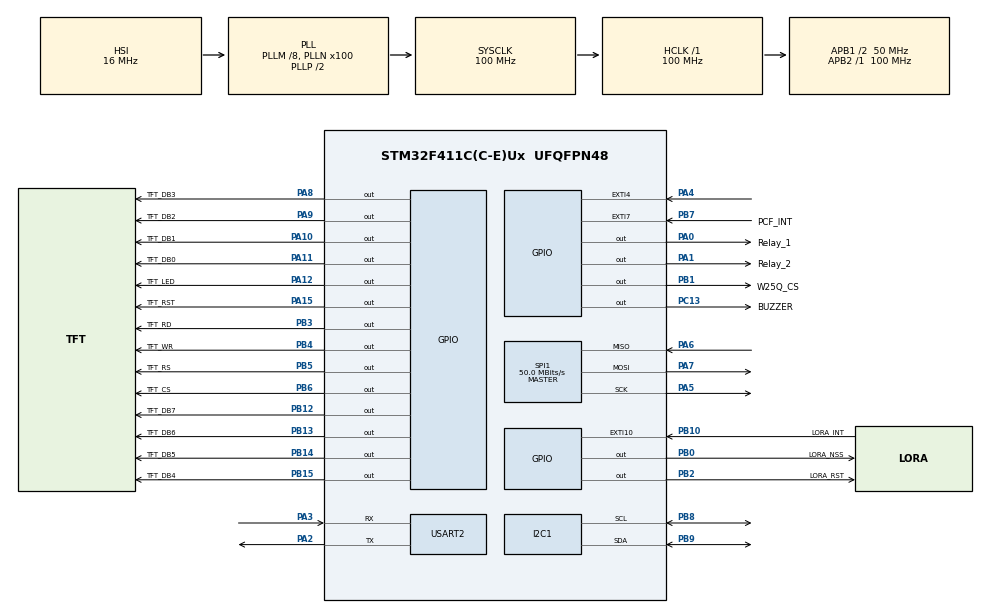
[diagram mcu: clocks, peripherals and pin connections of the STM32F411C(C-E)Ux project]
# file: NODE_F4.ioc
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FREERTOS.Tasks01=KeyMatrix_Task,0,128,StartKeyMatrix_Task,Default,NULL,Dynamic,NULL,NULL;TFT_Task,1,128,StartTFT_Task,Default,NULL,Dynamic,NULL,NULL
FREERTOS.configUSE_NEWLIB_REENTRANT=1
I2C1.DualAddressMode=I2C_DUALADDRESS_DISABLE
I2C1.GeneralCallMode=I2C_GENERALCALL_DISABLE
Mcu.Family=STM32F4
Mcu.Name=STM32F411C(C-E)Ux
Mcu.Package=UFQFPN48
NVIC.EXTI15_10_IRQn=true\:5\:0\:false\:false\:true\:true\:true\:true\:true
NVIC.EXTI9_5_IRQn=true\:5\:0\:false\:false\:true\:true\:true\:true\:true
NVIC.PriorityGroup=NVIC_PRIORITYGROUP_4
NVIC.TIM2_IRQn=true\:15\:0\:false\:false\:true\:false\:false\:true\:true
NVIC.TimeBase=TIM2_IRQn
NVIC.TimeBaseIP=TIM2
PA0-WKUP.GPIO_Label=Relay_1
PA0-WKUP.Signal=GPIO_Output
PA1.GPIO_Label=Relay_2
PA1.Signal=GPIO_Output
PA10.GPIO_Label=TFT_DB1
PA10.Signal=GPIO_Output
PA11.GPIO_Label=TFT_DB0
PA11.Signal=GPIO_Output
PA12.GPIO_Label=TFT_LED
PA12.Signal=GPIO_Output
PA13.Mode=Serial_Wire
PA13.Signal=SYS_JTMS-SWDIO
PA14.Mode=Serial_Wire
PA14.Signal=SYS_JTCK-SWCLK
PA15.GPIO_Label=TFT_RST
PA15.Signal=GPIO_Output
PA2.Mode=Asynchronous
PA2.Signal=USART2_TX
PA3.Mode=Asynchronous
PA3.Signal=USART2_RX
PA4.Signal=GPXTI4
PA5.Mode=Full_Duplex_Master
PA5.Signal=SPI1_SCK
PA6.Mode=Full_Duplex_Master
PA6.Signal=SPI1_MISO
PA7.Mode=Full_Duplex_Master
PA7.Signal=SPI1_MOSI
PA8.GPIO_Label=TFT_DB3
PA8.Signal=GPIO_Output
PA9.GPIO_Label=TFT_DB2
PA9.Signal=GPIO_Output
PB0.GPIO_Label=LORA_NSS
PB0.Signal=GPIO_Output
PB1.GPIO_Label=W25Q_CS
PB1.Signal=GPIO_Output
PB10.GPIO_Label=LORA_INT
PB10.Signal=GPXTI10
PB12.GPIO_Label=TFT_DB7
PB12.Signal=GPIO_Output
PB13.GPIO_Label=TFT_DB6
PB13.Signal=GPIO_Output
PB14.GPIO_Label=TFT_DB5
PB14.Signal=GPIO_Output
PB15.GPIO_Label=TFT_DB4
PB15.Signal=GPIO_Output
PB2.GPIO_Label=LORA_RST
PB2.Signal=GPIO_Output
PB3.GPIO_Label=TFT_RD
PB3.Signal=GPIO_Output
PB4.GPIO_Label=TFT_WR
PB4.Signal=GPIO_Output
PB5.GPIO_Label=TFT_RS
PB5.Signal=GPIO_Output
PB6.GPIO_Label=TFT_CS
PB6.Signal=GPIO_Output
PB7.GPIO_Label=PCF_INT
PB7.GPIO_ModeDefaultEXTI=GPIO_MODE_IT_FALLING
PB7.GPIO_PuPd=GPIO_PULLUP
PB7.Signal=GPXTI7
PB8.Mode=I2C
PB8.Signal=I2C1_SCL
PB9.Mode=I2C
PB9.Signal=I2C1_SDA
PC13-ANTI_TAMP.GPIO_Label=BUZZER
PC13-ANTI_TAMP.PinState=GPIO_PIN_RESET
PC13-ANTI_TAMP.Signal=GPIO_Output
PH0\ -\ OSC_IN.Mode=HSE-External-Oscillator
PH0\ -\ OSC_IN.Signal=RCC_OSC_IN
PH1\ -\ OSC_OUT.Mode=HSE-External-Oscillator
PH1\ -\ OSC_OUT.Signal=RCC_OSC_OUT
ProjectManager.HeapSize=0x200
ProjectManager.StackSize=0x400
ProjectManager.TargetToolchain=STM32CubeIDE
RCC.48MHZClocksFreq_Value=40000000
RCC.AHBFreq_Value=100000000
RCC.APB1CLKDivider=RCC_HCLK_DIV2
RCC.APB1Freq_Value=50000000
RCC.APB1TimFreq_Value=100000000
RCC.APB2Freq_Value=100000000
RCC.APB2TimFreq_Value=100000000
RCC.CortexFreq_Value=100000000
RCC.HCLKFreq_Value=100000000
RCC.HSE_VALUE=25000000
RCC.HSI_VALUE=16000000
RCC.LSE_VALUE=32768
RCC.PLLM=8
RCC.PLLN=100
RCC.PLLQ=5
RCC.SYSCLKFreq_VALUE=100000000
RCC.SYSCLKSource=RCC_SYSCLKSOURCE_PLLCLK
RCC.VCOOutputFreq_Value=200000000
SPI1.CalculateBaudRate=50.0 MBits/s
SPI1.Direction=SPI_DIRECTION_2LINES
SPI1.Mode=SPI_MODE_MASTER
SPI1.VirtualType=VM_MASTER
TIM3.Prescaler=71
USART2.VirtualMode=VM_ASYNC
VP_FREERTOS_VS_CMSIS_V1.Mode=CMSIS_V1
VP_SYS_VS_tim2.Mode=TIM2
VP_TIM3_VS_ClockSourceINT.Mode=Internal
board=custom

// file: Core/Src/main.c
/* USER CODE BEGIN Header */
/**
  ******************************************************************************
  * @file           : main.c
  * @brief          : Main program body
  ******************************************************************************
  * @attention
  *
  * Copyright (c) 2023 STMicroelectronics.
  * All rights reserved.
  *
  * This software is licensed under terms that can be found in the LICENSE file
  * in the root directory of this software component.
  * If no LICENSE file comes with this software, it is provided AS-IS.
  *
  ******************************************************************************
  */
/* USER CODE END Header */
#include "main.h"
#include "cmsis_os.h"

/* USER CODE BEGIN Includes */
#include "TFT.h"
/* USER CODE END Includes */

I2C_HandleTypeDef hi2c1;

SPI_HandleTypeDef hspi1;

TIM_HandleTypeDef htim3;

UART_HandleTypeDef huart2;

osThreadId KeyMatrix_TaskHandle;
osThreadId TFT_TaskHandle;

void SystemClock_Config(void);
static void MX_GPIO_Init(void);
static void MX_I2C1_Init(void);
static void MX_SPI1_Init(void);
static void MX_USART2_UART_Init(void);
static void MX_TIM3_Init(void);
void StartKeyMatrix_Task(void const * argument);
void StartTFT_Task(void const * argument);

int main(void)
{

  /* MCU Configuration--------------------------------------------------------*/

  /* Reset of all peripherals, Initializes the Flash interface and the Systick. */
  HAL_Init();

  /* Configure the system clock */
  SystemClock_Config();

  /* Initialize all configured peripherals */
  MX_GPIO_Init();
  MX_I2C1_Init();
  MX_SPI1_Init();
  MX_USART2_UART_Init();
  MX_TIM3_Init();
  /* USER CODE BEGIN 2 */
  TFT_init();
  /* USER CODE END 2 */

  /* Create the thread(s) */
  /* definition and creation of KeyMatrix_Task */
  osThreadDef(KeyMatrix_Task, StartKeyMatrix_Task, osPriorityNormal, 0, 128);
  KeyMatrix_TaskHandle = osThreadCreate(osThread(KeyMatrix_Task), NULL);

  /* definition and creation of TFT_Task */
  osThreadDef(TFT_Task, StartTFT_Task, osPriorityAboveNormal, 0, 128);
  TFT_TaskHandle = osThreadCreate(osThread(TFT_Task), NULL);

  /* Start scheduler */
  osKernelStart();

  /* We should never get here as control is now taken by the scheduler */
  /* Infinite loop */
  while (1)
  {

  }
}

void SystemClock_Config(void)
{
  RCC_OscInitTypeDef RCC_OscInitStruct = {0};
  RCC_ClkInitTypeDef RCC_ClkInitStruct = {0};

  /** Configure the main internal regulator output voltage
  */
  __HAL_RCC_PWR_CLK_ENABLE();
  __HAL_PWR_VOLTAGESCALING_CONFIG(PWR_REGULATOR_VOLTAGE_SCALE1);

  /** Initializes the RCC Oscillators according to the specified parameters
  * in the RCC_OscInitTypeDef structure.
  */
  RCC_OscInitStruct.OscillatorType = RCC_OSCILLATORTYPE_HSI;
  RCC_OscInitStruct.HSIState = RCC_HSI_ON;
  RCC_OscInitStruct.HSICalibrationValue = RCC_HSICALIBRATION_DEFAULT;
  RCC_OscInitStruct.PLL.PLLState = RCC_PLL_ON;
  RCC_OscInitStruct.PLL.PLLSource = RCC_PLLSOURCE_HSI;
  RCC_OscInitStruct.PLL.PLLM = 8;
  RCC_OscInitStruct.PLL.PLLN = 100;
  RCC_OscInitStruct.PLL.PLLP = RCC_PLLP_DIV2;
  RCC_OscInitStruct.PLL.PLLQ = 5;
  if (HAL_RCC_OscConfig(&RCC_OscInitStruct) != HAL_OK)
  {
    Error_Handler();
  }

  /** Initializes the CPU, AHB and APB buses clocks
  */
  RCC_ClkInitStruct.ClockType = RCC_CLOCKTYPE_HCLK|RCC_CLOCKTYPE_SYSCLK
                              |RCC_CLOCKTYPE_PCLK1|RCC_CLOCKTYPE_PCLK2;
  RCC_ClkInitStruct.SYSCLKSource = RCC_SYSCLKSOURCE_PLLCLK;
  RCC_ClkInitStruct.AHBCLKDivider = RCC_SYSCLK_DIV1;
  RCC_ClkInitStruct.APB1CLKDivider = RCC_HCLK_DIV2;
  RCC_ClkInitStruct.APB2CLKDivider = RCC_HCLK_DIV1;

  if (HAL_RCC_ClockConfig(&RCC_ClkInitStruct, FLASH_LATENCY_3) != HAL_OK)
  {
    Error_Handler();
  }
}

static void MX_I2C1_Init(void)
{

  hi2c1.Instance = I2C1;
  hi2c1.Init.ClockSpeed = 100000;
  hi2c1.Init.DutyCycle = I2C_DUTYCYCLE_2;
  hi2c1.Init.OwnAddress1 = 0;
  hi2c1.Init.AddressingMode = I2C_ADDRESSINGMODE_7BIT;
  hi2c1.Init.DualAddressMode = I2C_DUALADDRESS_DISABLE;
  hi2c1.Init.OwnAddress2 = 0;
  hi2c1.Init.GeneralCallMode = I2C_GENERALCALL_DISABLE;
  hi2c1.Init.NoStretchMode = I2C_NOSTRETCH_DISABLE;
  if (HAL_I2C_Init(&hi2c1) != HAL_OK)
  {
    Error_Handler();
  }

}

static void MX_SPI1_Init(void)
{

  /* SPI1 parameter configuration*/
  hspi1.Instance = SPI1;
  hspi1.Init.Mode = SPI_MODE_MASTER;
  hspi1.Init.Direction = SPI_DIRECTION_2LINES;
  hspi1.Init.DataSize = SPI_DATASIZE_8BIT;
  hspi1.Init.CLKPolarity = SPI_POLARITY_LOW;
  hspi1.Init.CLKPhase = SPI_PHASE_1EDGE;
  hspi1.Init.NSS = SPI_NSS_SOFT;
  hspi1.Init.BaudRatePrescaler = SPI_BAUDRATEPRESCALER_2;
  hspi1.Init.FirstBit = SPI_FIRSTBIT_MSB;
  hspi1.Init.TIMode = SPI_TIMODE_DISABLE;
  hspi1.Init.CRCCalculation = SPI_CRCCALCULATION_DISABLE;
  hspi1.Init.CRCPolynomial = 10;
  if (HAL_SPI_Init(&hspi1) != HAL_OK)
  {
    Error_Handler();
  }

}

static void MX_TIM3_Init(void)
{

  TIM_ClockConfigTypeDef sClockSourceConfig = {0};
  TIM_MasterConfigTypeDef sMasterConfig = {0};

  htim3.Instance = TIM3;
  htim3.Init.Prescaler = 71;
  htim3.Init.CounterMode = TIM_COUNTERMODE_UP;
  htim3.Init.Period = 65535;
  htim3.Init.ClockDivision = TIM_CLOCKDIVISION_DIV1;
  htim3.Init.AutoReloadPreload = TIM_AUTORELOAD_PRELOAD_DISABLE;
  if (HAL_TIM_Base_Init(&htim3) != HAL_OK)
  {
    Error_Handler();
  }
  sClockSourceConfig.ClockSource = TIM_CLOCKSOURCE_INTERNAL;
  if (HAL_TIM_ConfigClockSource(&htim3, &sClockSourceConfig) != HAL_OK)
  {
    Error_Handler();
  }
  sMasterConfig.MasterOutputTrigger = TIM_TRGO_RESET;
  sMasterConfig.MasterSlaveMode = TIM_MASTERSLAVEMODE_DISABLE;
  if (HAL_TIMEx_MasterConfigSynchronization(&htim3, &sMasterConfig) != HAL_OK)
  {
    Error_Handler();
  }

}

static void MX_USART2_UART_Init(void)
{

  huart2.Instance = USART2;
  huart2.Init.BaudRate = 115200;
  huart2.Init.WordLength = UART_WORDLENGTH_8B;
  huart2.Init.StopBits = UART_STOPBITS_1;
  huart2.Init.Parity = UART_PARITY_NONE;
  huart2.Init.Mode = UART_MODE_TX_RX;
  huart2.Init.HwFlowCtl = UART_HWCONTROL_NONE;
  huart2.Init.OverSampling = UART_OVERSAMPLING_16;
  if (HAL_UART_Init(&huart2) != HAL_OK)
  {
    Error_Handler();
  }

}

static void MX_GPIO_Init(void)
{
  GPIO_InitTypeDef GPIO_InitStruct = {0};

  /* GPIO Ports Clock Enable */
  __HAL_RCC_GPIOC_CLK_ENABLE();
  __HAL_RCC_GPIOH_CLK_ENABLE();
  __HAL_RCC_GPIOA_CLK_ENABLE();
  __HAL_RCC_GPIOB_CLK_ENABLE();

  /*Configure GPIO pin Output Level */
  HAL_GPIO_WritePin(BUZZER_GPIO_Port, BUZZER_Pin, GPIO_PIN_RESET);

  /*Configure GPIO pin Output Level */
  HAL_GPIO_WritePin(GPIOA, Relay_1_Pin|Relay_2_Pin|TFT_DB3_Pin|TFT_DB2_Pin
                          |TFT_DB1_Pin|TFT_DB0_Pin|TFT_LED_Pin|TFT_RST_Pin, GPIO_PIN_RESET);

  /*Configure GPIO pin Output Level */
  HAL_GPIO_WritePin(GPIOB, LORA_NSS_Pin|W25Q_CS_Pin|LORA_RST_Pin|TFT_DB7_Pin
                          |TFT_DB6_Pin|TFT_DB5_Pin|TFT_DB4_Pin|TFT_RD_Pin
                          |TFT_WR_Pin|TFT_RS_Pin|TFT_CS_Pin, GPIO_PIN_RESET);

  /*Configure GPIO pin : BUZZER_Pin */
  GPIO_InitStruct.Pin = BUZZER_Pin;
  GPIO_InitStruct.Mode = GPIO_MODE_OUTPUT_PP;
  GPIO_InitStruct.Pull = GPIO_NOPULL;
  GPIO_InitStruct.Speed = GPIO_SPEED_FREQ_LOW;
  HAL_GPIO_Init(BUZZER_GPIO_Port, &GPIO_InitStruct);

  /*Configure GPIO pins : Relay_1_Pin Relay_2_Pin TFT_DB3_Pin TFT_DB2_Pin
                           TFT_DB1_Pin TFT_DB0_Pin TFT_LED_Pin TFT_RST_Pin */
  GPIO_InitStruct.Pin = Relay_1_Pin|Relay_2_Pin|TFT_DB3_Pin|TFT_DB2_Pin
                          |TFT_DB1_Pin|TFT_DB0_Pin|TFT_LED_Pin|TFT_RST_Pin;
  GPIO_InitStruct.Mode = GPIO_MODE_OUTPUT_PP;
  GPIO_InitStruct.Pull = GPIO_NOPULL;
  GPIO_InitStruct.Speed = GPIO_SPEED_FREQ_LOW;
  HAL_GPIO_Init(GPIOA, &GPIO_InitStruct);

  /*Configure GPIO pin : PA4 */
  GPIO_InitStruct.Pin = GPIO_PIN_4;
  GPIO_InitStruct.Mode = GPIO_MODE_IT_RISING;
  GPIO_InitStruct.Pull = GPIO_NOPULL;
  HAL_GPIO_Init(GPIOA, &GPIO_InitStruct);

  /*Configure GPIO pins : LORA_NSS_Pin W25Q_CS_Pin LORA_RST_Pin TFT_DB7_Pin
                           TFT_DB6_Pin TFT_DB5_Pin TFT_DB4_Pin TFT_RD_Pin
                           TFT_WR_Pin TFT_RS_Pin TFT_CS_Pin */
  GPIO_InitStruct.Pin = LORA_NSS_Pin|W25Q_CS_Pin|LORA_RST_Pin|TFT_DB7_Pin
                          |TFT_DB6_Pin|TFT_DB5_Pin|TFT_DB4_Pin|TFT_RD_Pin
                          |TFT_WR_Pin|TFT_RS_Pin|TFT_CS_Pin;
  GPIO_InitStruct.Mode = GPIO_MODE_OUTPUT_PP;
  GPIO_InitStruct.Pull = GPIO_NOPULL;
  GPIO_InitStruct.Speed = GPIO_SPEED_FREQ_LOW;
  HAL_GPIO_Init(GPIOB, &GPIO_InitStruct);

  /*Configure GPIO pin : LORA_INT_Pin */
  GPIO_InitStruct.Pin = LORA_INT_Pin;
  GPIO_InitStruct.Mode = GPIO_MODE_IT_RISING;
  GPIO_InitStruct.Pull = GPIO_NOPULL;
  HAL_GPIO_Init(LORA_INT_GPIO_Port, &GPIO_InitStruct);

  /*Configure GPIO pin : PCF_INT_Pin */
  GPIO_InitStruct.Pin = PCF_INT_Pin;
  GPIO_InitStruct.Mode = GPIO_MODE_IT_FALLING;
  GPIO_InitStruct.Pull = GPIO_PULLUP;
  HAL_GPIO_Init(PCF_INT_GPIO_Port, &GPIO_InitStruct);

  /* EXTI interrupt init*/
  HAL_NVIC_SetPriority(EXTI9_5_IRQn, 5, 0);
  HAL_NVIC_EnableIRQ(EXTI9_5_IRQn);

  HAL_NVIC_SetPriority(EXTI15_10_IRQn, 5, 0);
  HAL_NVIC_EnableIRQ(EXTI15_10_IRQn);

}

void StartKeyMatrix_Task(void const * argument)
{
  for(;;)
  {
	  osDelay(1);
  }
}

void StartTFT_Task(void const * argument)
{
  for(;;)
  {
	  osDelay(1);
  }
}

void HAL_TIM_PeriodElapsedCallback(TIM_HandleTypeDef *htim)
{
  if (htim->Instance == TIM2) {
    HAL_IncTick();
  }
}

void Error_Handler(void)
{
  __disable_irq();
  while (1)
  {
  }
}
